# PIC32MZ2048EFM144 register map
Vendor: Microchip
Registers are 32-bit, read-write, reset 0x0 unless marked. A register's access mark holds for its fields unless they carry their own. Addresses are absolute, and some are shared; only a register's first bit layout is shown; [hi:lo] are bit positions; {n}, {i} and the like mark numbered series.

## CRYPTO
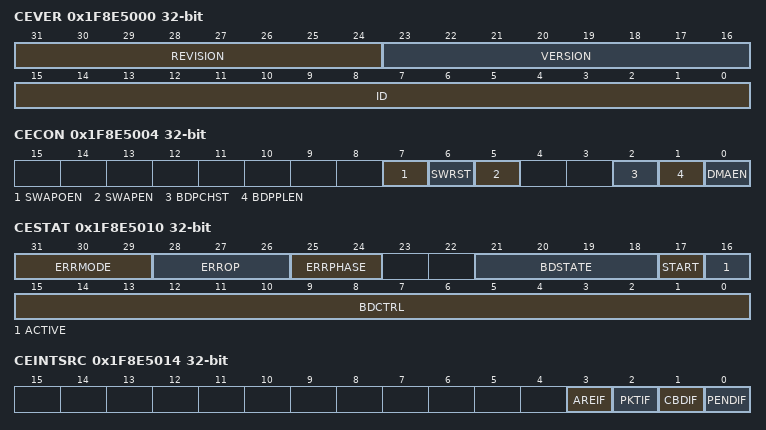
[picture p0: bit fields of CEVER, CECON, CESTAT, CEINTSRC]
0x1F8E5000 CEVER ro reset not defined — (power-on value xxxxxxxxxxxxxxxxxxxxxxxxxxxxxxxx)
  [31:24] REVISION, [23:16] VERSION, [15:0] ID
0x1F8E5004 CECON
  [7] SWAPOEN, [6] SWRST, [5] SWAPEN, [2] BDPCHST, [1] BDPPLEN, [0] DMAEN
0x1F8E5008 CEBDADDR ro
  [31:0] BDPADDR
0x1F8E500C CEBDPADDR ro
  [31:0] BASEADDR
0x1F8E5010 CESTAT ro
  [31:29] ERRMODE, [28:26] ERROP, [25:24] ERRPHASE, [21:18] BDSTATE, [17] START, [16] ACTIVE, [15:0] BDCTRL
0x1F8E5014 CEINTSRC ro
  [3] AREIF, [2] PKTIF, [1] CBDIF, [0] PENDIF
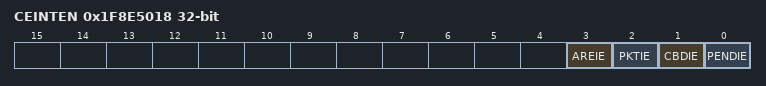
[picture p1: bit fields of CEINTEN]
0x1F8E5018 CEINTEN
  [3] AREIE, [2] PKTIE, [1] CBDIE, [0] PENDIE
0x1F8E501C CEPOLLCON
  [15:0] BDPPLCON
0x1F8E5020 CEHDLEN
  [7:0] HDRLEN
0x1F8E5024 CETRLLEN
  [7:0] TRLRLEN

## RNG
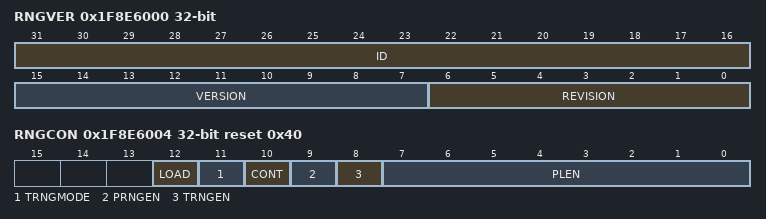
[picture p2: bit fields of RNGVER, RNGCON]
0x1F8E6000 RNGVER ro
  [31:16] ID, [15:7] VERSION, [6:0] REVISION
0x1F8E6004 RNGCON reset 0x40
  [12] LOAD, [11] TRNGMODE, [10] CONT, [9] PRNGEN, [8] TRNGEN, [7:0] PLEN
0x1F8E6008 RNGPOLY1 reset 0xFFFF0000
  [31:0] POLY
0x1F8E600C RNGPOLY2 reset 0xFFFF0000
  [31:0] POLY
0x1F8E6010 RNGNUMGEN1 reset 0xFFFFFFFF
  [31:0] RNG
0x1F8E6014 RNGNUMGEN2 reset 0xFFFFFFFF
  [31:0] RNG
0x1F8E6018 RNGSEED1 ro
  [31:0] SEED
0x1F8E601C RNGSEED2 ro
  [31:0] SEED
0x1F8E6020 RNGCNT
  [6:0] RCNT

## SB
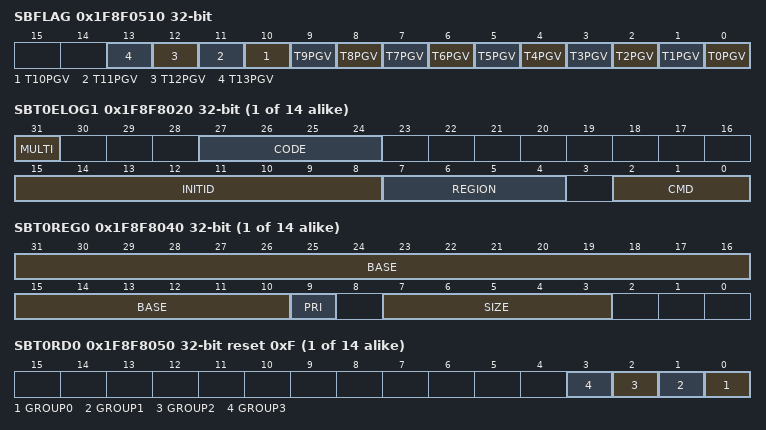
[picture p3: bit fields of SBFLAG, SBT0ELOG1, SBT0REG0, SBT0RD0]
0x1F8F0510 SBFLAG ro
  [n] T{n}PGV (n=0..13)
{0x1F8F8020+0x400*i} SBT{i}ELOG1 (i=0..13)
  [31] MULTI, [27:24] CODE, [15:8] INITID ro, [7:4] REGION ro, [2:0] CMD ro
{0x1F8F8024+0x400*i} SBT{i}ELOG2 ro (i=0..13)
  [1:0] GROUP
{0x1F8F8028+0x400*i} SBT{i}ECON (i=0..13)
  [24] ERRP
{0x1F8F8030+0x400*i} SBT{i}ECLRS ro (i=0..13)
  [0] CLEAR
{0x1F8F8038+0x400*i} SBT{i}ECLRM ro (i=0..13)
  [0] CLEAR
{0x1F8F8040+0x400*i} SBT{i}REG0 reset not defined (i=0..13) — (power-on value 0000000000000000000000x-00000---)
  [31:10] BASE, [9] PRI ro, [7:3] SIZE
{0x1F8F8050+0x400*i} SBT{i}RD0 reset 0xF (i=0..13)
  [n] GROUP{n} (n=0..3)
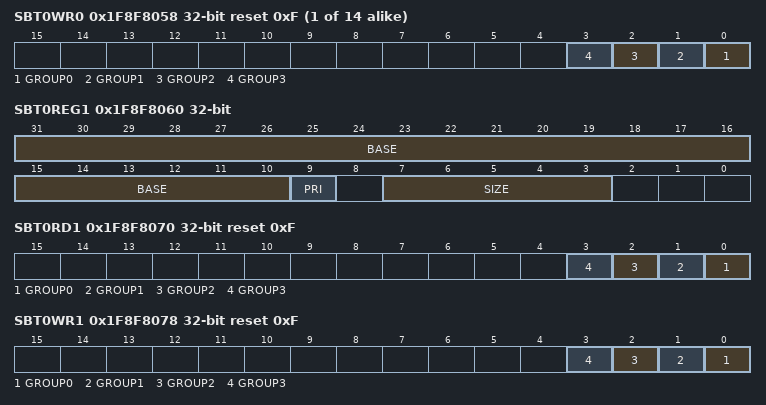
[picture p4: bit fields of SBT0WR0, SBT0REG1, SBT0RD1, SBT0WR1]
{0x1F8F8058+0x400*i} SBT{i}WR0 reset 0xF (i=0..13)
  [n] GROUP{n} (n=0..3)
0x1F8F8060 SBT0REG1 reset not defined — (power-on value 0000000000000000000000x-00000---)
  [31:10] BASE, [9] PRI ro, [7:3] SIZE
0x1F8F8070 SBT0RD1 reset 0xF
  [n] GROUP{n} (n=0..3)
0x1F8F8078 SBT0WR1 reset 0xF
  [n] GROUP{n} (n=0..3)
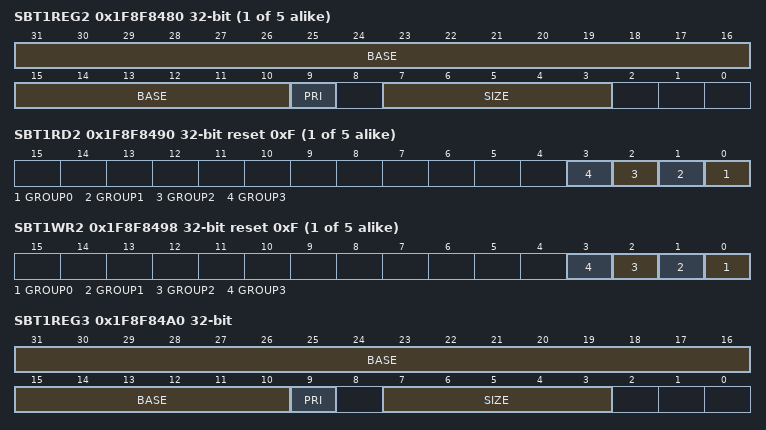
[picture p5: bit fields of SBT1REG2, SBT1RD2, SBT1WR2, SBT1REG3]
{0x1F8F8080+0x400*i} SBT{i}REG2 reset not defined (i=1..5) — (power-on value 0000000000000000000000x-00000---)
  [31:10] BASE, [9] PRI ro, [7:3] SIZE
{0x1F8F8090+0x400*i} SBT{i}RD2 reset 0xF (i=1..5)
  [n] GROUP{n} (n=0..3)
{0x1F8F8098+0x400*i} SBT{i}WR2 reset 0xF (i=1..5)
  [n] GROUP{n} (n=0..3)
0x1F8F84A0 SBT1REG3 reset not defined — (power-on value 0000000000000000000000x-00000---)
  [31:10] BASE, [9] PRI ro, [7:3] SIZE
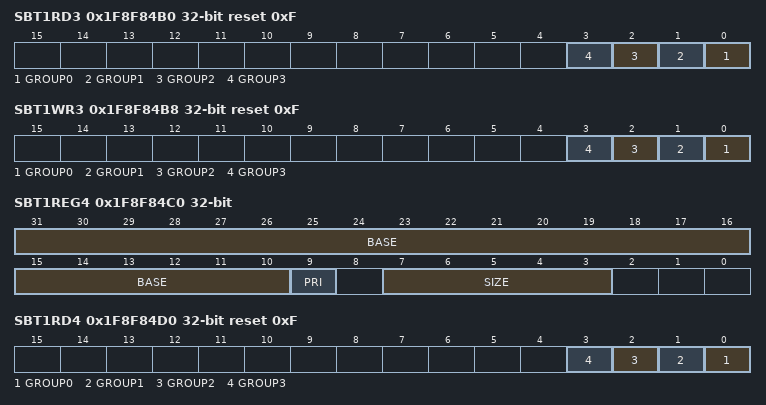
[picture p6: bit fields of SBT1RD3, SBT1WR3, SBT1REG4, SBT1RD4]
0x1F8F84B0 SBT1RD3 reset 0xF
  [n] GROUP{n} (n=0..3)
0x1F8F84B8 SBT1WR3 reset 0xF
  [n] GROUP{n} (n=0..3)
0x1F8F84C0 SBT1REG4 reset not defined — (power-on value 0000000000000000000000x-00000---)
  [31:10] BASE, [9] PRI ro, [7:3] SIZE
0x1F8F84D0 SBT1RD4 reset 0xF
  [n] GROUP{n} (n=0..3)
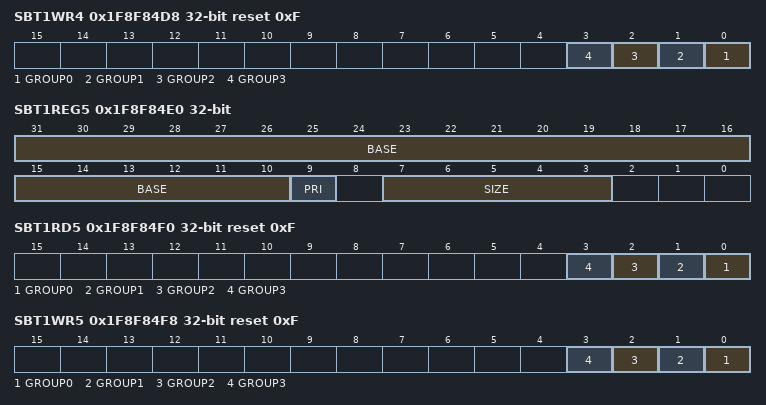
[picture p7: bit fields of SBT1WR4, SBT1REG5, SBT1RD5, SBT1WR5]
0x1F8F84D8 SBT1WR4 reset 0xF
  [n] GROUP{n} (n=0..3)
0x1F8F84E0 SBT1REG5 reset not defined — (power-on value 0000000000000000000000x-00000---)
  [31:10] BASE, [9] PRI ro, [7:3] SIZE
0x1F8F84F0 SBT1RD5 reset 0xF
  [n] GROUP{n} (n=0..3)
0x1F8F84F8 SBT1WR5 reset 0xF
  [n] GROUP{n} (n=0..3)
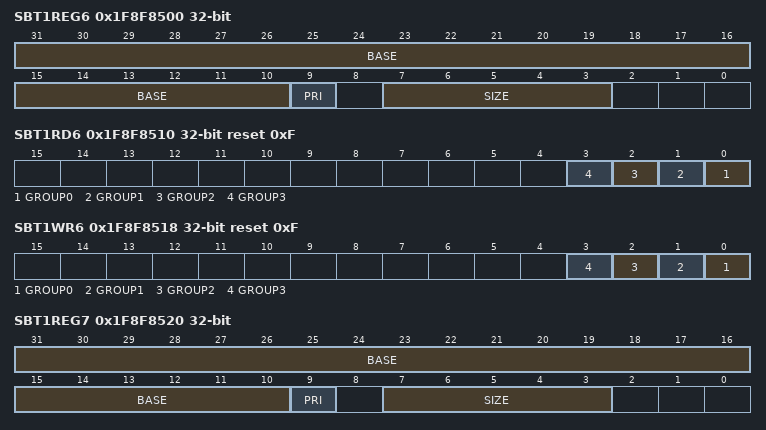
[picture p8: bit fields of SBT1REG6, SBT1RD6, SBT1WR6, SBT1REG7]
0x1F8F8500 SBT1REG6 reset not defined — (power-on value 0000000000000000000000x-00000---)
  [31:10] BASE, [9] PRI ro, [7:3] SIZE
0x1F8F8510 SBT1RD6 reset 0xF
  [n] GROUP{n} (n=0..3)
0x1F8F8518 SBT1WR6 reset 0xF
  [n] GROUP{n} (n=0..3)
0x1F8F8520 SBT1REG7 reset not defined — (power-on value 0000000000000000000000x-00000---)
  [31:10] BASE, [9] PRI ro, [7:3] SIZE
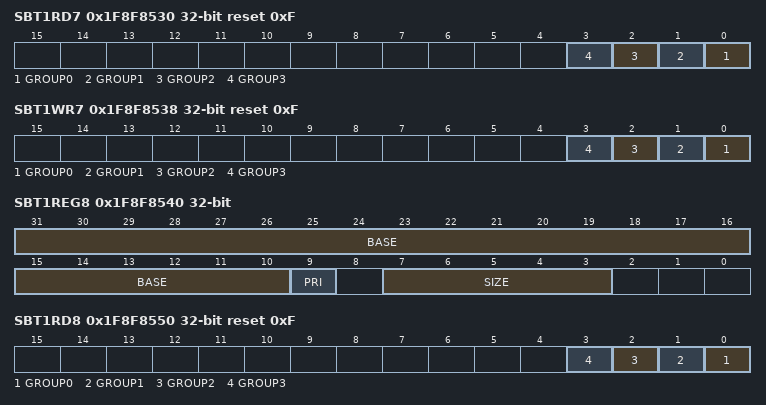
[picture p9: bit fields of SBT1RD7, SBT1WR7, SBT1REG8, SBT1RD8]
0x1F8F8530 SBT1RD7 reset 0xF
  [n] GROUP{n} (n=0..3)
0x1F8F8538 SBT1WR7 reset 0xF
  [n] GROUP{n} (n=0..3)
0x1F8F8540 SBT1REG8 reset not defined — (power-on value 0000000000000000000000x-00000---)
  [31:10] BASE, [9] PRI ro, [7:3] SIZE
0x1F8F8550 SBT1RD8 reset 0xF
  [n] GROUP{n} (n=0..3)
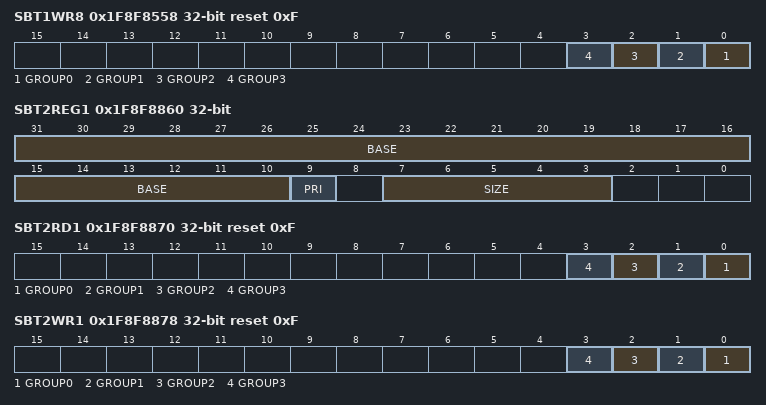
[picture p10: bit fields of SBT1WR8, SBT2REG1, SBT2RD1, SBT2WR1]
0x1F8F8558 SBT1WR8 reset 0xF
  [n] GROUP{n} (n=0..3)
0x1F8F8860 SBT2REG1 reset not defined — (power-on value 0000000000000000000000x-00000---)
  [31:10] BASE, [9] PRI ro, [7:3] SIZE
0x1F8F8870 SBT2RD1 reset 0xF
  [n] GROUP{n} (n=0..3)
0x1F8F8878 SBT2WR1 reset 0xF
  [n] GROUP{n} (n=0..3)
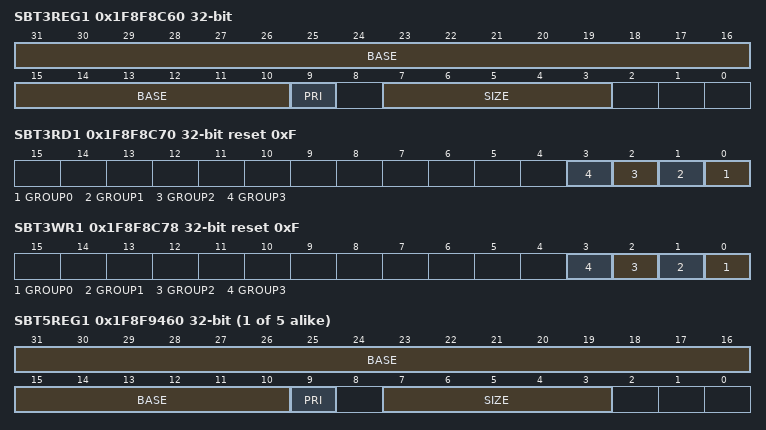
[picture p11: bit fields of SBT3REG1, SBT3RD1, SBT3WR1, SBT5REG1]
0x1F8F8C60 SBT3REG1 reset not defined — (power-on value 0000000000000000000000x-00000---)
  [31:10] BASE, [9] PRI ro, [7:3] SIZE
0x1F8F8C70 SBT3RD1 reset 0xF
  [n] GROUP{n} (n=0..3)
0x1F8F8C78 SBT3WR1 reset 0xF
  [n] GROUP{n} (n=0..3)
{0x1F8F8060+0x400*i} SBT{i}REG1 reset not defined (i=5..9) — (power-on value 0000000000000000000000x-00000---)
  [31:10] BASE, [9] PRI ro, [7:3] SIZE
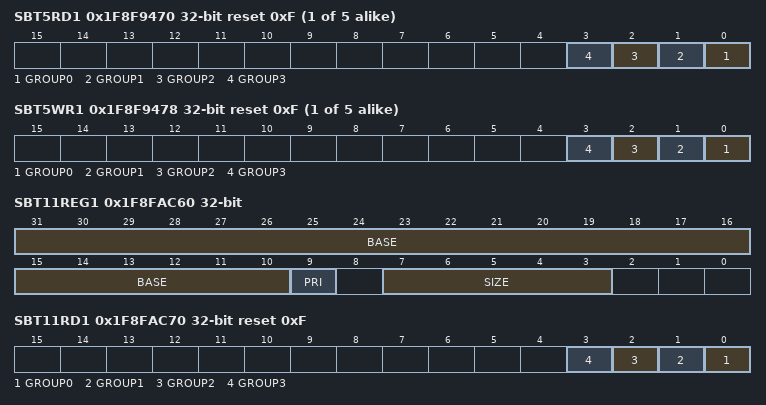
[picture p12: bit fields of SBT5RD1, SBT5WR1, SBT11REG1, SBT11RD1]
{0x1F8F8070+0x400*i} SBT{i}RD1 reset 0xF (i=5..9)
  [n] GROUP{n} (n=0..3)
{0x1F8F8078+0x400*i} SBT{i}WR1 reset 0xF (i=5..9)
  [n] GROUP{n} (n=0..3)
0x1F8FAC60 SBT11REG1 reset not defined — (power-on value 0000000000000000000000x-00000---)
  [31:10] BASE, [9] PRI ro, [7:3] SIZE
0x1F8FAC70 SBT11RD1 reset 0xF
  [n] GROUP{n} (n=0..3)
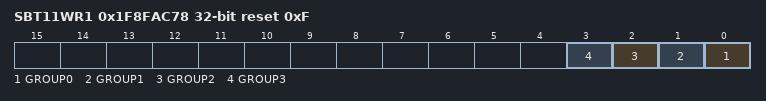
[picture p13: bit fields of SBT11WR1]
0x1F8FAC78 SBT11WR1 reset 0xF
  [n] GROUP{n} (n=0..3)
